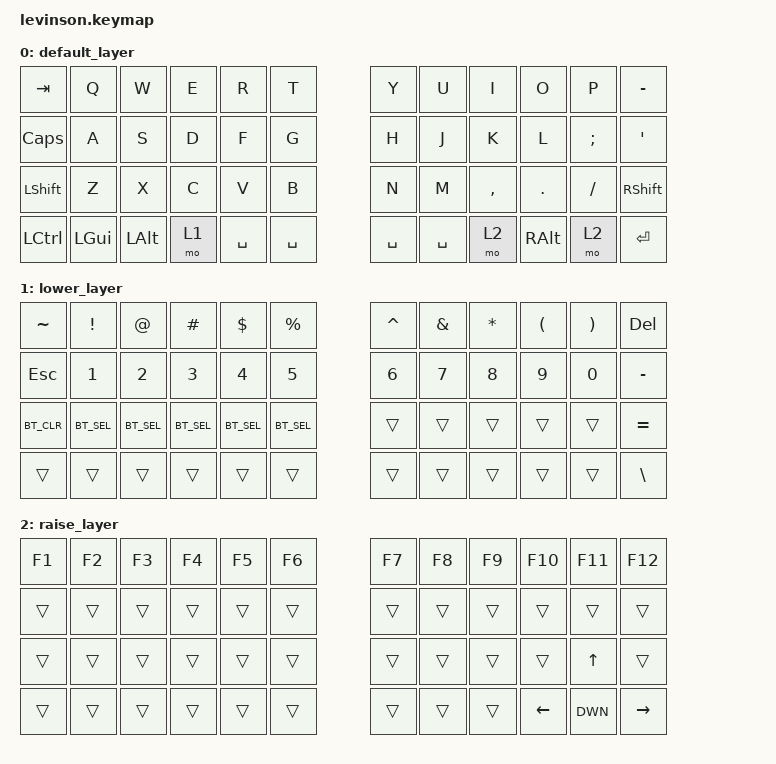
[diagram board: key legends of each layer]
/*
 * Copyright (c) 2020 The ZMK Contributors
 *
 * SPDX-License-Identifier: MIT
 */

 #include <behaviors.dtsi>
 #include <dt-bindings/zmk/keys.h>
 #include <dt-bindings/zmk/bt.h>

/ {
	keymap {
		compatible = "zmk,keymap";

		default_layer {
// ------------------------------------------------------------------------------------------------------------
// |  TAB  |  Q  |  W  |  E  |  R  |  T  |              |  Y  |  U  |  I  |  O  |  P  | BSPC  |
// | CAPS  |  A  |  S  |  D  |  F  |  G  |              |  H  |  J  |  K  |  L  |  ;  |   '   |
// | SHIFT |  Z  |  X  |  C  |  V  |  B  |              |  N  |  M  |  ,  |  .  |  /  | SHIFT |
// | CTRL  | WIN | ALT | LWR | SPC | SPC |              | SPC | SPC | RSE | ALT | DEL |  RET  |
			bindings = <
&kp TAB   &kp Q    &kp W    &kp E  &kp R   &kp T               &kp Y   &kp U   &kp I     &kp O    &kp P    &kp MINUS
&kp CAPS  &kp A    &kp S    &kp D  &kp F   &kp G               &kp H   &kp J   &kp K     &kp L    &kp SEMI &kp SQT
&kp LSHFT &kp Z    &kp X    &kp C  &kp V   &kp B               &kp N   &kp M   &kp COMMA &kp DOT  &kp FSLH &kp RSHFT
&kp LCTRL &kp LGUI &kp LALT &mo 1  &kp SPC &kp SPC             &kp SPC &kp SPC &mo 2     &kp RALT &mo 2    &kp RET
			>;
		};

		lower_layer {
// ------------------------------------------------------------------------------------------------------------
// |  ESC  |  !  |  @  |  #  |  $  |  %  |              |  ^  |  &  |  *  |  (  |  )  |  DEL  |
// |   `   |  1  |  2  |  3  |  4  |  5  |              |  6  |  7  |  8  |  9  |  0  | MINUS |
// | BTCLR | BT1 | BT2 | BT3 | BT4 | BT5 |              |     |     |     |     |     | EQUAL |
// |       |     |     |     |     |     |              |     |     |     |     |     | BSLH  | 
			bindings = <
&kp TILDE  &kp EXCL     &kp AT       &kp HASH     &kp DLLR     &kp PRCNT              &kp CARET &kp AMPS  &kp ASTRK &kp LPAR &kp RPAR &kp DEL
&kp ESC    &kp N1       &kp N2       &kp N3       &kp N4       &kp N5                 &kp N6    &kp N7    &kp N8    &kp N9   &kp N0   &kp MINUS
&kp BT_CLR &kp BT_SEL 1 &kp BT_SEL 2 &kp BT_SEL 3 &kp BT_SEL 4 &kp BT_SEL 5           &trans    &trans    &trans    &trans   &trans   &kp EQUAL       					              
&trans     &trans       &trans       &trans       &trans       &trans                 &trans    &trans    &trans    &trans   &trans   &kp BSLH			
            >;
		};

		raise_layer {
// ------------------------------------------------------------------------------------------------------------
// |  F1   |  F2 |  F3 |  F4 |  F5 |  F6 |              |  F7 |  F8 |  F9 | F10 | F11 |  F12  |
// |       |     |     |     |     |     |              |     |     |     |     |     |       |
// |       |     |     |     |     |     |              |     |     |     |     |  UP |       |
// |       |     |     |     |     |     |              |     |     |     | LFT | DWN | RIGHT |
			bindings = <
&kp F1  &kp F2  &kp F3  &kp F4  &kp F5  &kp F6              &kp F7  &kp F8  &kp F9  &kp F10  &kp F11 &kp F12
&trans  &trans  &trans  &trans  &trans  &trans              &trans  &trans  &trans  &trans   &trans  &trans
&trans  &trans  &trans  &trans  &trans  &trans              &trans  &trans  &trans  &trans   &kp UP  &trans
&trans  &trans  &trans  &trans  &trans  &trans              &trans  &trans  &trans  &kp LEFT &kp DWN &kp RIGHT
			>;
		};
	};
};
